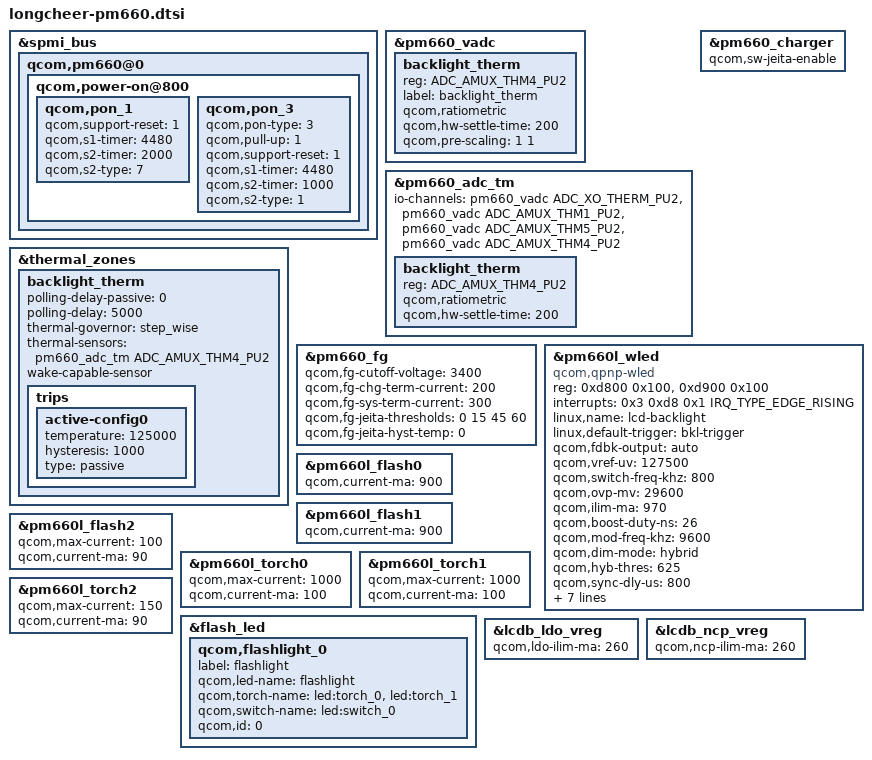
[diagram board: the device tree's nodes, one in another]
// SPDX-License-Identifier: GPL-2.0-only

/* common diff with msm-pm660.dtsi */
&spmi_bus {
	qcom,pm660@0 {
		qcom,power-on@800 {
			qcom,pon_1 {
				qcom,support-reset = <1>;
				qcom,s1-timer = <4480>;
				qcom,s2-timer = <2000>;
				qcom,s2-type = <7>;
			};

			qcom,pon_3 {
				qcom,pon-type = <3>;
				qcom,pull-up = <1>;
				qcom,support-reset = <1>;
				qcom,s1-timer = <4480>;
				qcom,s2-timer = <1000>;
				qcom,s2-type = <1>;
			};
		};
	};
};

&pm660_vadc {
	backlight_therm {
		reg = <ADC_AMUX_THM4_PU2>;
		label = "backlight_therm";
		qcom,ratiometric;
		qcom,hw-settle-time = <200>;
		qcom,pre-scaling = <1 1>;
	};
};

&pm660_adc_tm {
	io-channels = <&pm660_vadc ADC_XO_THERM_PU2>,
			<&pm660_vadc ADC_AMUX_THM1_PU2>,
			<&pm660_vadc ADC_AMUX_THM5_PU2>,
			<&pm660_vadc ADC_AMUX_THM4_PU2>;

	backlight_therm {
		reg = <ADC_AMUX_THM4_PU2>;
		qcom,ratiometric;
		qcom,hw-settle-time = <200>;
	};
};

&thermal_zones {
	backlight_therm {
		polling-delay-passive = <0>;
		polling-delay = <5000>;
		thermal-governor = "step_wise";
		thermal-sensors = <&pm660_adc_tm ADC_AMUX_THM4_PU2>;
		wake-capable-sensor;
		trips {
			active-config0 {
				temperature = <125000>;
				hysteresis = <1000>;
				type = "passive";
			};
		};
	};

	/delete-node/ ibat-high;
	/delete-node/ ibat-vhigh;
	/delete-node/ vbat_adc;
	/delete-node/ vbat_low;
	/delete-node/ vbat_too_low;
	/delete-node/ soc;
};

&pm660_charger {
	qcom,sw-jeita-enable;
};

&pm660_fg {
	qcom,fg-cutoff-voltage = <3400>;
	qcom,fg-chg-term-current = <200>;
	qcom,fg-sys-term-current = <300>;
	qcom,fg-jeita-thresholds = <0 15 45 60>;
	qcom,fg-jeita-hyst-temp = <0>;
};

/* common diff with msm-pm660l.dtsi */
&pm660l_wled {
	compatible = "qcom,qpnp-wled";
	reg = <0xd800 0x100>,
	      <0xd900 0x100>;
	reg-names = "qpnp-wled-ctrl-base",
		    "qpnp-wled-sink-base";
	interrupts = <0x3 0xd8 0x1 IRQ_TYPE_EDGE_RISING>;
	interrupt-names = "ovp-irq";
	linux,name = "lcd-backlight";
	linux,default-trigger = "bkl-trigger";
	qcom,fdbk-output = "auto";
	qcom,vref-uv = <127500>;
	qcom,switch-freq-khz = <800>;
	qcom,ovp-mv = <29600>;
	qcom,ilim-ma = <970>;
	qcom,boost-duty-ns = <26>;
	qcom,mod-freq-khz = <9600>;
	qcom,dim-mode = "hybrid";
	qcom,hyb-thres = <625>;
	qcom,sync-dly-us = <800>;
	qcom,fs-curr-ua = <20000>;
	qcom,cons-sync-write-delay-us = <1000>;
	qcom,led-strings-list = [00 01];
	qcom,en-cabc;
	qcom,loop-auto-gm-en;
	qcom,pmic-revid = <&pm660l_revid>;
	qcom,auto-calibration-enable;
	status = "ok";
	/delete-property/ qcom,string-cfg;
	/delete-property/ qcom,sync-dly;
	/delete-property/ qcom,auto-calibration;
	/delete-property/ qcom,fs-current-limit;
};

&pm660l_flash0 {
	qcom,current-ma = <900>;
};

&pm660l_flash1{
	qcom,current-ma = <900>;
};

&pm660l_flash2 {
	qcom,max-current = <100>;
	qcom,current-ma = <90>;
};

&pm660l_torch0 {
	qcom,max-current = <1000>;
	qcom,current-ma = <100>;
};

&pm660l_torch1 {
	qcom,max-current = <1000>;
	qcom,current-ma = <100>;
};

&pm660l_torch2 {
	qcom,max-current = <150>;
	qcom,current-ma = <90>;
};

&flash_led {
	qcom,flashlight_0 {
		label = "flashlight";
		qcom,led-name = "flashlight";
		qcom,torch-name = "led:torch_0", "led:torch_1";
		qcom,switch-name = "led:switch_0";
		qcom,id = <0>;
	};
};

&lcdb_ldo_vreg {
	qcom,ldo-ilim-ma = <260>;
};

&lcdb_ncp_vreg {
	qcom,ncp-ilim-ma = <260>;
};
